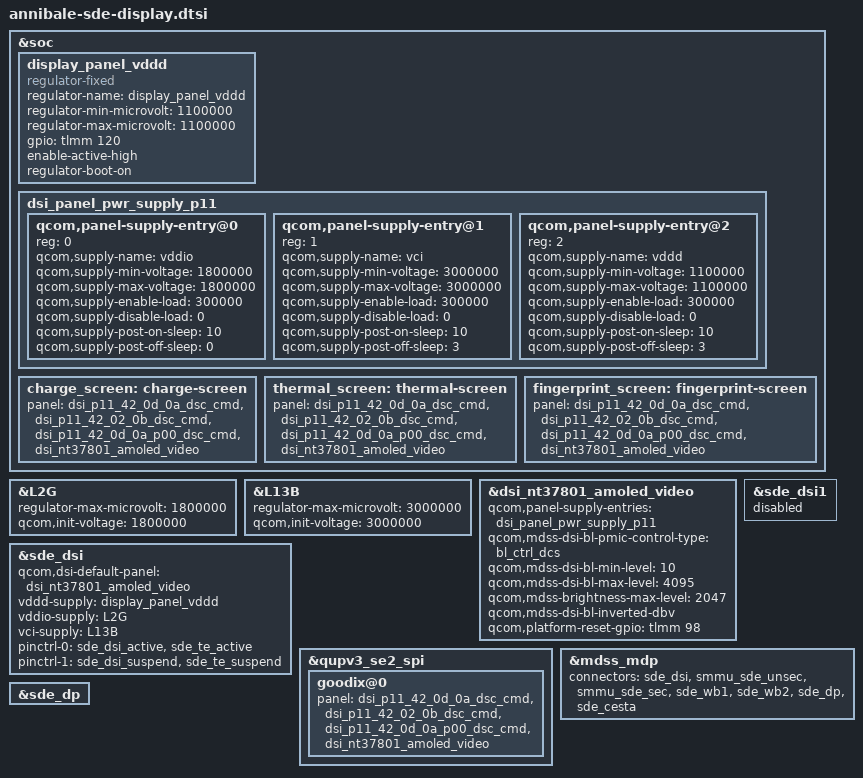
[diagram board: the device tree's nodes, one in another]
#include "sun-sde-display.dtsi"
#include "dsi-panel-p11-42-0d-0a-dsc-cmd.dtsi"
#include "dsi-panel-p11-42-02-0b-dsc-cmd.dtsi"
#include "dsi-panel-p11-42-0d-0a-p00-dsc-cmd.dtsi"
#include "dsi-panel-nt37801-dsc-wqhd-plus-video.dtsi"

&soc {
    	display_panel_vddd: display_panel_vddd {
		compatible = "regulator-fixed";
		regulator-name = "display_panel_vddd";
		regulator-min-microvolt = <1100000>;
		regulator-max-microvolt = <1100000>;
		gpio = <&tlmm 120 0>;
		enable-active-high;
		regulator-boot-on;
    };

	dsi_panel_pwr_supply_p11: dsi_panel_pwr_supply_p11 {
		qcom,panel-supply-entry@0 {
			reg = <0>;
			qcom,supply-name = "vddio";
			qcom,supply-min-voltage = <1800000>;
			qcom,supply-max-voltage = <1800000>;
			qcom,supply-enable-load = <300000>;
			qcom,supply-disable-load = <0>;
			qcom,supply-post-on-sleep = <10>;
			qcom,supply-post-off-sleep = <0>;
		};
		qcom,panel-supply-entry@1 {
			reg = <1>;
			qcom,supply-name = "vci";
			qcom,supply-min-voltage = <3000000>;
			qcom,supply-max-voltage = <3000000>;
			qcom,supply-enable-load = <300000>;
			qcom,supply-disable-load = <0>;
			qcom,supply-post-on-sleep = <10>;
			qcom,supply-post-off-sleep = <3>;
		};
		qcom,panel-supply-entry@2 {
			reg = <2>;
			qcom,supply-name = "vddd";
			qcom,supply-min-voltage = <1100000>;
			qcom,supply-max-voltage = <1100000>;
			qcom,supply-enable-load = <300000>;
			qcom,supply-disable-load = <0>;
			qcom,supply-post-on-sleep = <10>;
			qcom,supply-post-off-sleep = <3>;
		};
	};
};

&L2G {
		regulator-max-microvolt = <1800000>;
		qcom,init-voltage = <1800000>;
};

&L13B {
		regulator-max-microvolt = <3000000>;
		qcom,init-voltage = <3000000>;
};
&dsi_nt37801_amoled_video {
	qcom,panel-supply-entries = <&dsi_panel_pwr_supply_p11>;
	qcom,mdss-dsi-bl-pmic-control-type = "bl_ctrl_dcs";
	qcom,mdss-dsi-bl-min-level = <10>;
	qcom,mdss-dsi-bl-max-level = <4095>;
	qcom,mdss-brightness-max-level = <2047>;
	qcom,mdss-dsi-bl-inverted-dbv;
	qcom,platform-reset-gpio = <&tlmm 98 0>;
};

&sde_dsi {
	qcom,dsi-default-panel = <&dsi_nt37801_amoled_video>;
	vddd-supply = <&display_panel_vddd>;
	vddio-supply = <&L2G>;
	vci-supply = <&L13B>;
	pinctrl-names = "panel_active", "panel_suspend";
	pinctrl-0 = <&sde_dsi_active &sde_te_active>;
	pinctrl-1 = <&sde_dsi_suspend &sde_te_suspend>;
};

&qupv3_se2_spi {
		goodix@0 {
			panel  = <&dsi_p11_42_0d_0a_dsc_cmd
				&dsi_p11_42_02_0b_dsc_cmd
				&dsi_p11_42_0d_0a_p00_dsc_cmd
				&dsi_nt37801_amoled_video>;
        };
};

&sde_dsi1 {
	status = "disabled";
};

&mdss_mdp {
	connectors = <&sde_dsi &smmu_sde_unsec &smmu_sde_sec &sde_wb1 &sde_wb2 &sde_dp &sde_cesta>;
};

&sde_dp {
	status = "ok";
};

&soc {
	charge_screen: charge-screen {
		panel  = <&dsi_p11_42_0d_0a_dsc_cmd
			&dsi_p11_42_02_0b_dsc_cmd
			&dsi_p11_42_0d_0a_p00_dsc_cmd
			&dsi_nt37801_amoled_video>;
	};
};

&soc {
	thermal_screen: thermal-screen {
		panel = <&dsi_p11_42_0d_0a_dsc_cmd
			&dsi_p11_42_02_0b_dsc_cmd
			&dsi_p11_42_0d_0a_p00_dsc_cmd
			&dsi_nt37801_amoled_video>;
	};
	fingerprint_screen: fingerprint-screen {
		panel = <&dsi_p11_42_0d_0a_dsc_cmd
			&dsi_p11_42_02_0b_dsc_cmd
			&dsi_p11_42_0d_0a_p00_dsc_cmd
			&dsi_nt37801_amoled_video>;
	};
};
